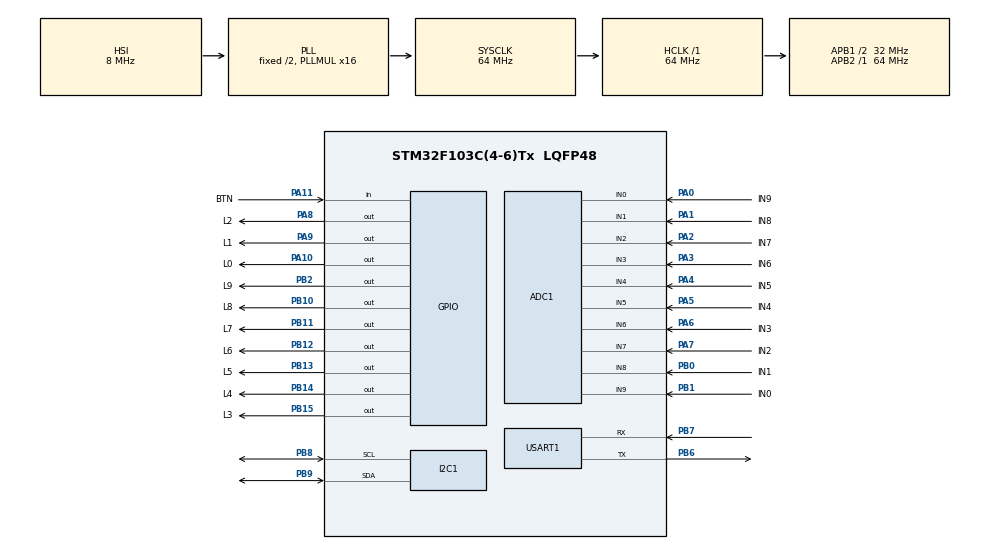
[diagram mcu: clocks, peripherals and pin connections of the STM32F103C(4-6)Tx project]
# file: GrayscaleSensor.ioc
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ADC1.Channel-0\#ChannelRegularConversion=ADC_CHANNEL_9
ADC1.Channel-1\#ChannelRegularConversion=ADC_CHANNEL_8
ADC1.Channel-2\#ChannelRegularConversion=ADC_CHANNEL_7
ADC1.Channel-3\#ChannelRegularConversion=ADC_CHANNEL_6
ADC1.Channel-4\#ChannelRegularConversion=ADC_CHANNEL_5
ADC1.Channel-5\#ChannelRegularConversion=ADC_CHANNEL_4
ADC1.Channel-6\#ChannelRegularConversion=ADC_CHANNEL_3
ADC1.Channel-7\#ChannelRegularConversion=ADC_CHANNEL_2
ADC1.Channel-8\#ChannelRegularConversion=ADC_CHANNEL_1
ADC1.Channel-9\#ChannelRegularConversion=ADC_CHANNEL_0
ADC1.ContinuousConvMode=DISABLE
ADC1.NbrOfConversion=10
ADC1.NbrOfConversionFlag=1
ADC1.Rank-0\#ChannelRegularConversion=1
ADC1.Rank-1\#ChannelRegularConversion=2
ADC1.Rank-2\#ChannelRegularConversion=3
ADC1.Rank-3\#ChannelRegularConversion=4
ADC1.Rank-4\#ChannelRegularConversion=5
ADC1.Rank-5\#ChannelRegularConversion=6
ADC1.Rank-6\#ChannelRegularConversion=7
ADC1.Rank-7\#ChannelRegularConversion=8
ADC1.Rank-8\#ChannelRegularConversion=9
ADC1.Rank-9\#ChannelRegularConversion=10
ADC1.SamplingTime-0\#ChannelRegularConversion=ADC_SAMPLETIME_28CYCLES_5
ADC1.SamplingTime-1\#ChannelRegularConversion=ADC_SAMPLETIME_28CYCLES_5
ADC1.SamplingTime-2\#ChannelRegularConversion=ADC_SAMPLETIME_28CYCLES_5
ADC1.SamplingTime-3\#ChannelRegularConversion=ADC_SAMPLETIME_28CYCLES_5
ADC1.SamplingTime-4\#ChannelRegularConversion=ADC_SAMPLETIME_28CYCLES_5
ADC1.SamplingTime-5\#ChannelRegularConversion=ADC_SAMPLETIME_28CYCLES_5
ADC1.SamplingTime-6\#ChannelRegularConversion=ADC_SAMPLETIME_28CYCLES_5
ADC1.SamplingTime-7\#ChannelRegularConversion=ADC_SAMPLETIME_28CYCLES_5
ADC1.SamplingTime-8\#ChannelRegularConversion=ADC_SAMPLETIME_28CYCLES_5
ADC1.SamplingTime-9\#ChannelRegularConversion=ADC_SAMPLETIME_28CYCLES_5
ADC1.master=1
Dma.ADC1.0.Direction=DMA_PERIPH_TO_MEMORY
Dma.ADC1.0.Instance=DMA1_Channel1
Dma.ADC1.0.MemDataAlignment=DMA_MDATAALIGN_WORD
Dma.ADC1.0.MemInc=DMA_MINC_ENABLE
Dma.ADC1.0.Mode=DMA_NORMAL
Dma.ADC1.0.PeriphDataAlignment=DMA_PDATAALIGN_HALFWORD
Dma.ADC1.0.PeriphInc=DMA_PINC_DISABLE
Dma.ADC1.0.Priority=DMA_PRIORITY_LOW
Dma.Request0=ADC1
Mcu.Family=STM32F1
Mcu.Name=STM32F103C(4-6)Tx
Mcu.Package=LQFP48
NVIC.ADC1_2_IRQn=true\:0\:0\:false\:false\:true\:true\:true\:true
NVIC.DMA1_Channel1_IRQn=true\:0\:0\:false\:false\:true\:false\:true\:true
NVIC.PriorityGroup=NVIC_PRIORITYGROUP_4
PA0-WKUP.GPIO_Label=IN9
PA0-WKUP.Signal=ADCx_IN0
PA1.GPIO_Label=IN8
PA1.Signal=ADCx_IN1
PA10.GPIO_Label=L0
PA10.GPIO_ModeDefaultOutputPP=GPIO_MODE_OUTPUT_OD
PA10.GPIO_PuPd=GPIO_PULLUP
PA10.GPIO_Speed=GPIO_SPEED_FREQ_LOW
PA10.PinState=GPIO_PIN_SET
PA10.Signal=GPIO_Output
PA11.GPIO_Label=BTN
PA11.GPIO_PuPd=GPIO_PULLUP
PA11.Signal=GPIO_Input
PA13.GPIO_Label=SWDIO
PA13.Mode=Serial_Wire
PA13.Signal=SYS_JTMS-SWDIO
PA14.GPIO_Label=SWCLK
PA14.Mode=Serial_Wire
PA14.Signal=SYS_JTCK-SWCLK
PA2.GPIO_Label=IN7
PA2.Signal=ADCx_IN2
PA3.GPIO_Label=IN6
PA3.Signal=ADCx_IN3
PA4.GPIO_Label=IN5
PA4.Signal=ADCx_IN4
PA5.GPIO_Label=IN4
PA5.Signal=ADCx_IN5
PA6.GPIO_Label=IN3
PA6.Signal=ADCx_IN6
PA7.GPIO_Label=IN2
PA7.Signal=ADCx_IN7
PA8.GPIO_Label=L2
PA8.GPIO_ModeDefaultOutputPP=GPIO_MODE_OUTPUT_OD
PA8.GPIO_PuPd=GPIO_PULLUP
PA8.GPIO_Speed=GPIO_SPEED_FREQ_LOW
PA8.PinState=GPIO_PIN_SET
PA8.Signal=GPIO_Output
PA9.GPIO_Label=L1
PA9.GPIO_ModeDefaultOutputPP=GPIO_MODE_OUTPUT_OD
PA9.GPIO_PuPd=GPIO_PULLUP
PA9.GPIO_Speed=GPIO_SPEED_FREQ_LOW
PA9.PinState=GPIO_PIN_SET
PA9.Signal=GPIO_Output
PB0.GPIO_Label=IN1
PB0.Signal=ADCx_IN8
PB1.GPIO_Label=IN0
PB1.Signal=ADCx_IN9
PB10.GPIO_Label=L8
PB10.GPIO_ModeDefaultOutputPP=GPIO_MODE_OUTPUT_OD
PB10.GPIO_PuPd=GPIO_PULLUP
PB10.GPIO_Speed=GPIO_SPEED_FREQ_LOW
PB10.PinState=GPIO_PIN_SET
PB10.Signal=GPIO_Output
PB11.GPIO_Label=L7
PB11.GPIO_ModeDefaultOutputPP=GPIO_MODE_OUTPUT_OD
PB11.GPIO_PuPd=GPIO_PULLUP
PB11.GPIO_Speed=GPIO_SPEED_FREQ_LOW
PB11.PinState=GPIO_PIN_SET
PB11.Signal=GPIO_Output
PB12.GPIO_Label=L6
PB12.GPIO_ModeDefaultOutputPP=GPIO_MODE_OUTPUT_OD
PB12.GPIO_PuPd=GPIO_PULLUP
PB12.GPIO_Speed=GPIO_SPEED_FREQ_LOW
PB12.PinState=GPIO_PIN_SET
PB12.Signal=GPIO_Output
PB13.GPIO_Label=L5
PB13.GPIO_ModeDefaultOutputPP=GPIO_MODE_OUTPUT_OD
PB13.GPIO_PuPd=GPIO_PULLUP
PB13.GPIO_Speed=GPIO_SPEED_FREQ_LOW
PB13.PinState=GPIO_PIN_SET
PB13.Signal=GPIO_Output
PB14.GPIO_Label=L4
PB14.GPIO_ModeDefaultOutputPP=GPIO_MODE_OUTPUT_OD
PB14.GPIO_PuPd=GPIO_PULLUP
PB14.GPIO_Speed=GPIO_SPEED_FREQ_LOW
PB14.PinState=GPIO_PIN_SET
PB14.Signal=GPIO_Output
PB15.GPIO_Label=L3
PB15.GPIO_ModeDefaultOutputPP=GPIO_MODE_OUTPUT_OD
PB15.GPIO_PuPd=GPIO_PULLUP
PB15.GPIO_Speed=GPIO_SPEED_FREQ_LOW
PB15.PinState=GPIO_PIN_SET
PB15.Signal=GPIO_Output
PB2.GPIO_Label=L9
PB2.GPIO_ModeDefaultOutputPP=GPIO_MODE_OUTPUT_OD
PB2.GPIO_PuPd=GPIO_PULLUP
PB2.GPIO_Speed=GPIO_SPEED_FREQ_LOW
PB2.PinState=GPIO_PIN_SET
PB2.Signal=GPIO_Output
PB6.Mode=Asynchronous
PB6.Signal=USART1_TX
PB7.Mode=Asynchronous
PB7.Signal=USART1_RX
PB8.Mode=I2C
PB8.Signal=I2C1_SCL
PB9.Mode=I2C
PB9.Signal=I2C1_SDA
ProjectManager.HeapSize=0x200
ProjectManager.StackSize=0x400
ProjectManager.TargetToolchain=MDK-ARM V5.32
RCC.ADCPresc=RCC_ADCPCLK2_DIV8
RCC.AHBFreq_Value=64000000
RCC.APB1CLKDivider=RCC_HCLK_DIV2
RCC.APB1Freq_Value=32000000
RCC.APB1TimFreq_Value=64000000
RCC.APB2Freq_Value=64000000
RCC.APB2TimFreq_Value=64000000
RCC.HCLKFreq_Value=64000000
RCC.PLLMUL=RCC_PLL_MUL16
RCC.SYSCLKFreq_VALUE=64000000
RCC.SYSCLKSource=RCC_SYSCLKSOURCE_PLLCLK
RCC.USBFreq_Value=64000000
SH.ADCx_IN0.0=ADC1_IN0,IN0
SH.ADCx_IN1.0=ADC1_IN1,IN1
SH.ADCx_IN2.0=ADC1_IN2,IN2
SH.ADCx_IN3.0=ADC1_IN3,IN3
SH.ADCx_IN4.0=ADC1_IN4,IN4
SH.ADCx_IN5.0=ADC1_IN5,IN5
SH.ADCx_IN6.0=ADC1_IN6,IN6
SH.ADCx_IN7.0=ADC1_IN7,IN7
SH.ADCx_IN8.0=ADC1_IN8,IN8
SH.ADCx_IN9.0=ADC1_IN9,IN9
USART1.VirtualMode=VM_ASYNC
VP_CRC_VS_CRC.Mode=CRC_Activate
board=custom

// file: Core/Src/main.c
/* USER CODE BEGIN Header */
/**
  ******************************************************************************
  * @file           : main.c
  * @brief          : Main program body
  ******************************************************************************
  * @attention
  *
  * Copyright (c) 2024 STMicroelectronics.
  * All rights reserved.
  *
  * This software is licensed under terms that can be found in the LICENSE file
  * in the root directory of this software component.
  * If no LICENSE file comes with this software, it is provided AS-IS.
  *
  ******************************************************************************
  */
/* USER CODE END Header */
#include "main.h"
#include "adc.h"
#include "crc.h"
#include "dma.h"
#include "i2c.h"
#include "usart.h"
#include "gpio.h"

/* USER CODE BEGIN Includes */
#include "app_main.h"
/* USER CODE END Includes */

void SystemClock_Config(void);

int main(void)
{

  /* MCU Configuration--------------------------------------------------------*/

  /* Reset of all peripherals, Initializes the Flash interface and the Systick. */
  HAL_Init();

  /* Configure the system clock */
  SystemClock_Config();

  /* Initialize all configured peripherals */
  MX_GPIO_Init();
  MX_DMA_Init();
  MX_ADC1_Init();
  MX_I2C1_Init();
  MX_USART1_UART_Init();
  MX_CRC_Init();
  /* USER CODE BEGIN 2 */
	Main_Init();
  /* USER CODE END 2 */

  /* Infinite loop */
  while (1)
  {

    /* USER CODE BEGIN 3 */
		Main_Process();
  }
  /* USER CODE END 3 */
}

void SystemClock_Config(void)
{
  RCC_OscInitTypeDef RCC_OscInitStruct = {0};
  RCC_ClkInitTypeDef RCC_ClkInitStruct = {0};
  RCC_PeriphCLKInitTypeDef PeriphClkInit = {0};

  /** Initializes the RCC Oscillators according to the specified parameters
  * in the RCC_OscInitTypeDef structure.
  */
  RCC_OscInitStruct.OscillatorType = RCC_OSCILLATORTYPE_HSI;
  RCC_OscInitStruct.HSIState = RCC_HSI_ON;
  RCC_OscInitStruct.HSICalibrationValue = RCC_HSICALIBRATION_DEFAULT;
  RCC_OscInitStruct.PLL.PLLState = RCC_PLL_ON;
  RCC_OscInitStruct.PLL.PLLSource = RCC_PLLSOURCE_HSI_DIV2;
  RCC_OscInitStruct.PLL.PLLMUL = RCC_PLL_MUL16;
  if (HAL_RCC_OscConfig(&RCC_OscInitStruct) != HAL_OK)
  {
    Error_Handler();
  }

  /** Initializes the CPU, AHB and APB buses clocks
  */
  RCC_ClkInitStruct.ClockType = RCC_CLOCKTYPE_HCLK|RCC_CLOCKTYPE_SYSCLK
                              |RCC_CLOCKTYPE_PCLK1|RCC_CLOCKTYPE_PCLK2;
  RCC_ClkInitStruct.SYSCLKSource = RCC_SYSCLKSOURCE_PLLCLK;
  RCC_ClkInitStruct.AHBCLKDivider = RCC_SYSCLK_DIV1;
  RCC_ClkInitStruct.APB1CLKDivider = RCC_HCLK_DIV2;
  RCC_ClkInitStruct.APB2CLKDivider = RCC_HCLK_DIV1;

  if (HAL_RCC_ClockConfig(&RCC_ClkInitStruct, FLASH_LATENCY_2) != HAL_OK)
  {
    Error_Handler();
  }
  PeriphClkInit.PeriphClockSelection = RCC_PERIPHCLK_ADC;
  PeriphClkInit.AdcClockSelection = RCC_ADCPCLK2_DIV8;
  if (HAL_RCCEx_PeriphCLKConfig(&PeriphClkInit) != HAL_OK)
  {
    Error_Handler();
  }
}

void Error_Handler(void)
{
  __disable_irq();
  while (1)
  {
  }
}
